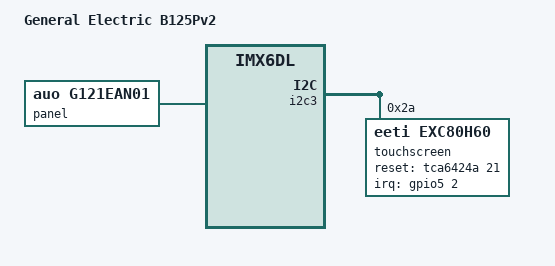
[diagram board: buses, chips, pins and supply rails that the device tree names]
// SPDX-License-Identifier: GPL-2.0 or MIT
//
// Device Tree Source for General Electric B125Pv2
//
// Copyright 2018-2021 General Electric Company
// Copyright 2018-2021 Collabora

/dts-v1/;
#include "imx6dl-b1x5pv2.dtsi"

/ {
	model = "General Electric B125Pv2";
	compatible = "ge,imx6dl-b125pv2", "congatec,qmx6", "fsl,imx6dl";

	panel {
		compatible = "auo,g121ean01";
	};
};

&i2c3 {
	touchscreen@2a {
		compatible = "eeti,exc80h60";
		reg = <0x2a>;
		pinctrl-names = "default";
		pinctrl-0 =<&pinctrl_q7_gpio0>;
		interrupt-parent = <&gpio5>;
		interrupts = <2 IRQ_TYPE_LEVEL_LOW>;
		reset-gpios = <&tca6424a 21 GPIO_ACTIVE_HIGH>;
	};
};
